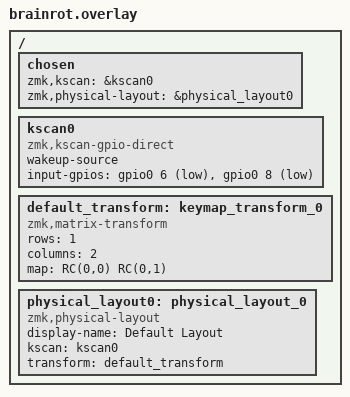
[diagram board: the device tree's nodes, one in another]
#include <dt-bindings/gpio/gpio.h>
#include <dt-bindings/zmk/matrix_transform.h>

/ {
    chosen {
        zmk,kscan = &kscan0;
        zmk,physical-layout = &physical_layout0;
    };

    kscan0: kscan0 {
        compatible = "zmk,kscan-gpio-direct";
        wakeup-source;

        input-gpios
            = <&gpio0 6 (GPIO_ACTIVE_LOW | GPIO_PULL_UP)>  /* P0.06 / синяя */
            , <&gpio0 8 (GPIO_ACTIVE_LOW | GPIO_PULL_UP)>  /* P0.08 / красная */
            ;
    };

    default_transform: keymap_transform_0 {
        compatible = "zmk,matrix-transform";
        rows = <1>;
        columns = <2>;
        map = <
            RC(0,0) RC(0,1)
        >;
    };

    physical_layout0: physical_layout_0 {
        compatible = "zmk,physical-layout";
        display-name = "Default Layout";
        kscan = <&kscan0>;
        transform = <&default_transform>;
    };
};
